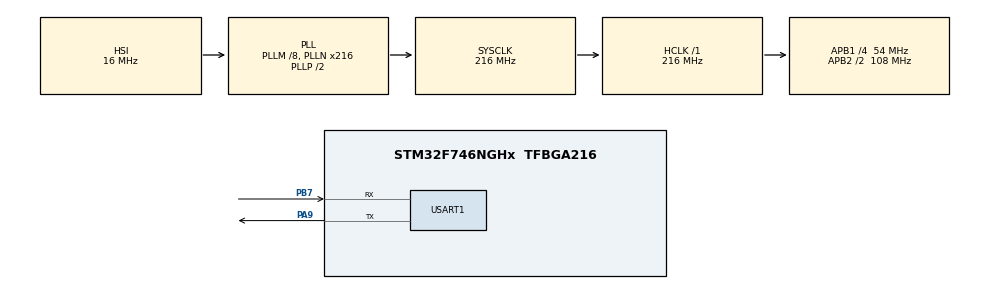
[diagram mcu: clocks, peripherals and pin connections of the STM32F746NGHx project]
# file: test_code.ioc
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FREERTOS.Tasks01=defaultTask,0,128,StartDefaultTask,Default,NULL,Dynamic,NULL,NULL
Mcu.Family=STM32F7
Mcu.Name=STM32F746NGHx
Mcu.Package=TFBGA216
NVIC.PriorityGroup=NVIC_PRIORITYGROUP_4
NVIC.TIM6_DAC_IRQn=true\:15\:0\:false\:false\:true\:false\:false\:true
NVIC.TimeBase=TIM6_DAC_IRQn
NVIC.TimeBaseIP=TIM6
PA13.Mode=Serial_Wire
PA13.Signal=SYS_JTMS-SWDIO
PA14.Mode=Serial_Wire
PA14.Signal=SYS_JTCK-SWCLK
PA9.Mode=Asynchronous
PA9.Signal=USART1_TX
PB7.Mode=Asynchronous
PB7.Signal=USART1_RX
PH0/OSC_IN.Mode=HSE-External-Oscillator
PH0/OSC_IN.Signal=RCC_OSC_IN
PH1/OSC_OUT.Mode=HSE-External-Oscillator
PH1/OSC_OUT.Signal=RCC_OSC_OUT
ProjectManager.HeapSize=0x200
ProjectManager.StackSize=0x400
ProjectManager.TargetToolchain=STM32CubeIDE
RCC.AHBFreq_Value=216000000
RCC.APB1CLKDivider=RCC_HCLK_DIV4
RCC.APB1Freq_Value=54000000
RCC.APB1TimFreq_Value=108000000
RCC.APB2CLKDivider=RCC_HCLK_DIV2
RCC.APB2Freq_Value=108000000
RCC.APB2TimFreq_Value=216000000
RCC.CortexFreq_Value=216000000
RCC.HCLKFreq_Value=216000000
RCC.HSE_VALUE=25000000
RCC.HSI_VALUE=16000000
RCC.LSE_VALUE=32768
RCC.PLLM=25
RCC.PLLN=432
RCC.PLLSourceVirtual=RCC_PLLSOURCE_HSE
RCC.SYSCLKFreq_VALUE=216000000
RCC.SYSCLKSource=RCC_SYSCLKSOURCE_PLLCLK
RCC.USBFreq_Value=216000000
RCC.VCOOutputFreq_Value=432000000
USART1.VirtualMode-Asynchronous=VM_ASYNC
VP_FREERTOS_VS_CMSIS_V1.Mode=CMSIS_V1
VP_SYS_VS_tim6.Mode=TIM6
board=STM32F746G-DISCO

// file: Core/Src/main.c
/* USER CODE BEGIN Header */
/**
 ******************************************************************************
 * @file           : main.c
 * @brief          : Main program body
 ******************************************************************************
 * @attention
 *
 * <h2><center>&copy; Copyright (c) 2021 STMicroelectronics.
 * All rights reserved.</center></h2>
 *
 * This software component is licensed by ST under BSD 3-Clause license,
 * the "License"; You may not use this file except in compliance with the
 * License. You may obtain a copy of the License at:
 *                        opensource.org/licenses/BSD-3-Clause
 *
 ******************************************************************************
 */
/* USER CODE END Header */
#include "main.h"
#include "cmsis_os.h"
#include "usart.h"
#include "gpio.h"

/* USER CODE BEGIN Includes */
#include <stdio.h>
/* USER CODE END Includes */

/* USER CODE BEGIN PD */
#define STACK_SIZE 256

#define TASK1_PRIORITY 1
#define TASK2_PRIORITY 2

#define TASK1_DELAY 1
#define TASK2_DELAY 2
/* USER CODE END PD */

void SystemClock_Config(void);
void MX_FREERTOS_Init(void);
SemaphoreHandle_t MutexExclusion;

/* USER CODE BEGIN 0 */
int __io_putchar(int ch) {
	HAL_UART_Transmit(&huart1, (uint8_t *)&ch, 1, HAL_MAX_DELAY);
	return ch;
}

// delay is in fact a critical value and must be handled with MUTEX

void vTask1(void * pvParameters) {
	int delay = (int) pvParameters;

	while(1) {
		xSemaphoreTake(MutexExclusion, 10);
		printf("Je suis la tache 1 et je m'endors pour %d ticks\r\n", delay);
		xSemaphoreGive(MutexExclusion);
		vTaskDelay(delay);

	}

}

void vTask2(void * pvParameters) {
	int delay = (int) pvParameters;

	while(1) {
		//Encapsulate as much as possible what we need
		xSemaphoreTake(MutexExclusion, 10);
		printf("Je suis la tache 2 et je m'endors pour %d ticks\r\n", delay);
		xSemaphoreGive(MutexExclusion);
		vTaskDelay(delay);
		}

}
/* USER CODE END 0 */

int main(void)
{
	/* USER CODE BEGIN 1 */
	BaseType_t xReturned;
	TaskHandle_t xHandle1 = NULL;
	TaskHandle_t xHandle2 = NULL;
	//Creation of Mutex Semaphore
	MutexExclusion= xSemaphoreCreateMutex();
	/* USER CODE END 1 */

	/* MCU Configuration--------------------------------------------------------*/

	/* Reset of all peripherals, Initializes the Flash interface and the Systick. */
	HAL_Init();

	/* USER CODE BEGIN Init */
	printf("\r\n==== TP1 Q4 ====\r\n");
	/* USER CODE END Init */

	/* Configure the system clock */
	SystemClock_Config();

	/* Initialize all configured peripherals */
	MX_GPIO_Init();
	MX_USART1_UART_Init();
	/* USER CODE BEGIN 2 */

	/* Create the task, storing the handle. */
	xReturned = xTaskCreate(vTask1, "Tache 1", STACK_SIZE, ( void * ) TASK1_DELAY, TASK1_PRIORITY, &xHandle1);
	configASSERT(xReturned == pdPASS);
	xReturned = xTaskCreate(vTask2, "Tache 2", STACK_SIZE, ( void * ) TASK2_DELAY, TASK2_PRIORITY, &xHandle2);
	configASSERT(xReturned == pdPASS);
	/* USER CODE END 2 */

	/* Call init function for freertos objects (in freertos.c) */
	MX_FREERTOS_Init();
	/* Start scheduler */
	osKernelStart();

	/* We should never get here as control is now taken by the scheduler */
	/* Infinite loop */
	while (1)
	{

	}
}

void SystemClock_Config(void)
{
	RCC_OscInitTypeDef RCC_OscInitStruct = {0};
	RCC_ClkInitTypeDef RCC_ClkInitStruct = {0};
	RCC_PeriphCLKInitTypeDef PeriphClkInitStruct = {0};

	/** Configure the main internal regulator output voltage
	 */
	__HAL_RCC_PWR_CLK_ENABLE();
	__HAL_PWR_VOLTAGESCALING_CONFIG(PWR_REGULATOR_VOLTAGE_SCALE1);
	/** Initializes the RCC Oscillators according to the specified parameters
	 * in the RCC_OscInitTypeDef structure.
	 */
	RCC_OscInitStruct.OscillatorType = RCC_OSCILLATORTYPE_HSI;
	RCC_OscInitStruct.HSIState = RCC_HSI_ON;
	RCC_OscInitStruct.HSICalibrationValue = RCC_HSICALIBRATION_DEFAULT;
	RCC_OscInitStruct.PLL.PLLState = RCC_PLL_ON;
	RCC_OscInitStruct.PLL.PLLSource = RCC_PLLSOURCE_HSI;
	RCC_OscInitStruct.PLL.PLLM = 8;
	RCC_OscInitStruct.PLL.PLLN = 216;
	RCC_OscInitStruct.PLL.PLLP = RCC_PLLP_DIV2;
	RCC_OscInitStruct.PLL.PLLQ = 2;
	if (HAL_RCC_OscConfig(&RCC_OscInitStruct) != HAL_OK)
	{
		Error_Handler();
	}
	/** Activate the Over-Drive mode
	 */
	if (HAL_PWREx_EnableOverDrive() != HAL_OK)
	{
		Error_Handler();
	}
	/** Initializes the CPU, AHB and APB buses clocks
	 */
	RCC_ClkInitStruct.ClockType = RCC_CLOCKTYPE_HCLK|RCC_CLOCKTYPE_SYSCLK
			|RCC_CLOCKTYPE_PCLK1|RCC_CLOCKTYPE_PCLK2;
	RCC_ClkInitStruct.SYSCLKSource = RCC_SYSCLKSOURCE_PLLCLK;
	RCC_ClkInitStruct.AHBCLKDivider = RCC_SYSCLK_DIV1;
	RCC_ClkInitStruct.APB1CLKDivider = RCC_HCLK_DIV4;
	RCC_ClkInitStruct.APB2CLKDivider = RCC_HCLK_DIV2;

	if (HAL_RCC_ClockConfig(&RCC_ClkInitStruct, FLASH_LATENCY_7) != HAL_OK)
	{
		Error_Handler();
	}
	PeriphClkInitStruct.PeriphClockSelection = RCC_PERIPHCLK_USART1;
	PeriphClkInitStruct.Usart1ClockSelection = RCC_USART1CLKSOURCE_PCLK2;
	if (HAL_RCCEx_PeriphCLKConfig(&PeriphClkInitStruct) != HAL_OK)
	{
		Error_Handler();
	}
}

void HAL_TIM_PeriodElapsedCallback(TIM_HandleTypeDef *htim)
{
	if (htim->Instance == TIM6) {
		HAL_IncTick();
	}
}

void Error_Handler(void)
{
}

/************************ (C) COPYRIGHT STMicroelectronics *****END OF FILE****/
